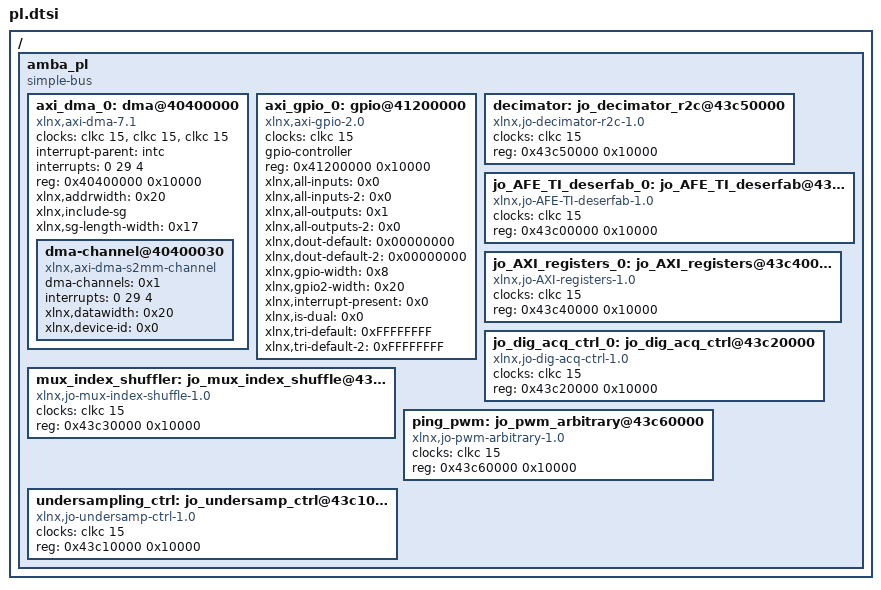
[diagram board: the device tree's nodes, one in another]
/*
 * CAUTION: This file is automatically generated by Xilinx.
 * Version:  
 * Today is: Fri May 15 15:13:16 2020
 */


/ {
	amba_pl: amba_pl {
		#address-cells = <1>;
		#size-cells = <1>;
		compatible = "simple-bus";
		ranges ;
		axi_dma_0: dma@40400000 {
			#dma-cells = <1>;
			clock-names = "s_axi_lite_aclk", "m_axi_sg_aclk", "m_axi_s2mm_aclk";
			clocks = <&clkc 15>, <&clkc 15>, <&clkc 15>;
			compatible = "xlnx,axi-dma-7.1", "xlnx,axi-dma-1.00.a";
			interrupt-names = "s2mm_introut";
			interrupt-parent = <&intc>;
			interrupts = <0 29 4>;
			reg = <0x40400000 0x10000>;
			xlnx,addrwidth = <0x20>;
			xlnx,include-sg ;
			xlnx,sg-length-width = <0x17>;
			dma-channel@40400030 {
				compatible = "xlnx,axi-dma-s2mm-channel";
				dma-channels = <0x1>;
				interrupts = <0 29 4>;
				xlnx,datawidth = <0x20>;
				xlnx,device-id = <0x0>;
			};
		};
		axi_gpio_0: gpio@41200000 {
			#gpio-cells = <3>;
			clock-names = "s_axi_aclk";
			clocks = <&clkc 15>;
			compatible = "xlnx,axi-gpio-2.0", "xlnx,xps-gpio-1.00.a";
			gpio-controller ;
			reg = <0x41200000 0x10000>;
			xlnx,all-inputs = <0x0>;
			xlnx,all-inputs-2 = <0x0>;
			xlnx,all-outputs = <0x1>;
			xlnx,all-outputs-2 = <0x0>;
			xlnx,dout-default = <0x00000000>;
			xlnx,dout-default-2 = <0x00000000>;
			xlnx,gpio-width = <0x8>;
			xlnx,gpio2-width = <0x20>;
			xlnx,interrupt-present = <0x0>;
			xlnx,is-dual = <0x0>;
			xlnx,tri-default = <0xFFFFFFFF>;
			xlnx,tri-default-2 = <0xFFFFFFFF>;
		};
		decimator: jo_decimator_r2c@43c50000 {
			clock-names = "clk";
			clocks = <&clkc 15>;
			compatible = "xlnx,jo-decimator-r2c-1.0";
			reg = <0x43c50000 0x10000>;
		};
		jo_AFE_TI_deserfab_0: jo_AFE_TI_deserfab@43c00000 {
			clock-names = "clk";
			clocks = <&clkc 15>;
			compatible = "xlnx,jo-AFE-TI-deserfab-1.0";
			reg = <0x43c00000 0x10000>;
		};
		jo_AXI_registers_0: jo_AXI_registers@43c40000 {
			clock-names = "clk";
			clocks = <&clkc 15>;
			compatible = "xlnx,jo-AXI-registers-1.0";
			reg = <0x43c40000 0x10000>;
		};
		jo_dig_acq_ctrl_0: jo_dig_acq_ctrl@43c20000 {
			clock-names = "clk";
			clocks = <&clkc 15>;
			compatible = "xlnx,jo-dig-acq-ctrl-1.0";
			reg = <0x43c20000 0x10000>;
		};
		mux_index_shuffler: jo_mux_index_shuffle@43c30000 {
			clock-names = "clk";
			clocks = <&clkc 15>;
			compatible = "xlnx,jo-mux-index-shuffle-1.0";
			reg = <0x43c30000 0x10000>;
		};
		ping_pwm: jo_pwm_arbitrary@43c60000 {
			clock-names = "clk";
			clocks = <&clkc 15>;
			compatible = "xlnx,jo-pwm-arbitrary-1.0";
			reg = <0x43c60000 0x10000>;
		};
		undersampling_ctrl: jo_undersamp_ctrl@43c10000 {
			clock-names = "clk";
			clocks = <&clkc 15>;
			compatible = "xlnx,jo-undersamp-ctrl-1.0";
			reg = <0x43c10000 0x10000>;
		};
	};
};
